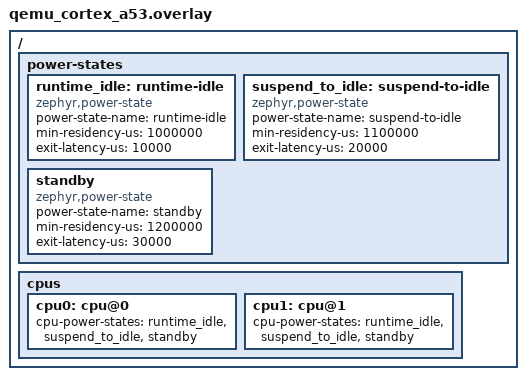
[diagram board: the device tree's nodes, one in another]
/*
 * CPU power states for qemu_cortex_a53.
 *
 * The board has none: dts/arm64/qemu/qemu-virt-a53.dtsi declares a bare `cpus`
 * node, and soc/arm/qemu_cortex_a53 does not `select HAS_PM`, so CONFIG_PM is
 * not even selectable there. What makes PM work anyway is the application:
 * samples/subsys/pm/latency has `select HAS_PM` in its own Kconfig and supplies
 * pm_state_set() / pm_state_exit_post_ops() in src/pm.c. That is the blessed
 * in-tree idiom (7 users), and it is why this is an overlay and not a patch to
 * the SoC.
 *
 * The numbers are copied verbatim from that sample's own
 * boards/native_sim.overlay, and they must stay that way. Its whole script is
 * calibrated to these three exit latencies: it sleeps 1.1 / 1.2 / 1.3 s and
 * then requests a 30 ms latency budget (which still allows standby), the test
 * device adds 20 ms (which blocks standby), and an update to 10 ms leaves only
 * runtime-idle. Change a number here and the sample's own log lines start
 * lying about what it expects to enter.
 *
 * Path-based, not `&cpu0`: the dtsi gives cpu@0 and cpu@1 no labels at all.
 * Declaring `cpu0:` here adds the label to the merged node, which also happens
 * to be what subsys/pm/pm_cpu_shell.c's DT_NODELABEL(cpu0) needs to compile.
 *
 * subsys/pm/policy/policy_default.c walks this list and BREAKS at the first
 * state whose min-residency + exit-latency does not fit the time to the next
 * timeout — it does not keep looking. So the list must stay sorted ascending by
 * that sum. It is: 1.01 s, 1.12 s, 1.23 s.
 *
 * No tick-rate override is needed. The board default is 100 Hz (kernel/Kconfig
 * picks that for QEMU_TARGET), i.e. a 10 ms tick, and the shallowest threshold
 * here is 101 ticks — tick granularity is irrelevant at second scale.
 */

/ {
	power-states {
		runtime_idle: runtime-idle {
			compatible = "zephyr,power-state";
			power-state-name = "runtime-idle";
			min-residency-us = <1000000>;
			exit-latency-us = <10000>;
		};

		suspend_to_idle: suspend-to-idle {
			compatible = "zephyr,power-state";
			power-state-name = "suspend-to-idle";
			min-residency-us = <1100000>;
			exit-latency-us = <20000>;
		};

		standby: standby {
			compatible = "zephyr,power-state";
			power-state-name = "standby";
			min-residency-us = <1200000>;
			exit-latency-us = <30000>;
		};
	};

	cpus {
		cpu0: cpu@0 {
			cpu-power-states = <&runtime_idle &suspend_to_idle &standby>;
		};

		/*
		 * cpu@1 is in the dtsi on every variant, including the non-SMP
		 * build this repo packages, and subsys/pm/state.c builds its
		 * per-CPU tables from DT_FOREACH_CHILD_STATUS_OKAY(/cpus). Give
		 * it the same ladder so the table entry is not zero-length and
		 * the /smp variant behaves identically.
		 */
		cpu1: cpu@1 {
			cpu-power-states = <&runtime_idle &suspend_to_idle &standby>;
		};
	};
};
